# alb32r003x register map
Vendor: ALB; Series: ALB RT SoC
CPU: ALB XF, little endian
Registers are 32-bit, access not given, reset 0x0 unless marked. A register's access mark holds for its fields unless they carry their own. Offsets are from the block's base; [hi:lo] are bit positions.

## PWR — PWR: power
Base 0x29000000
0x00 PWR_CR — PWR_CR: power control register
0x04 PWR_CSR — PWR_CSR: power status register
0x08 PWR_TEST — PWR_TEST: power test register

## WDT1 — WDT1: Independent Watchdog Timer 1 for fail-safe system reset on timeout
Base 0x29002000
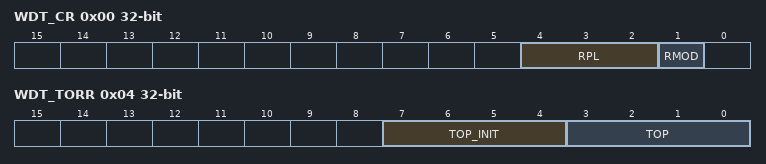
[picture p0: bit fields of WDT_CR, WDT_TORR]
0x00 WDT_CR rw — Control Register
  [4:2] RPL — Reset pulse length
    0=PCLK_CYCLES_2 (2 cycles); 1=PCLK_CYCLES_4 (4 cycles); 2=PCLK_CYCLES_8 (8 cycles); 3=PCLK_CYCLES_16 (16 cycles); 4=PCLK_CYCLES_32 (32 cycles); 5=PCLK_CYCLES_64 (64 cycles); 6=PCLK_CYCLES_128 (128 cycles); 7=PCLK_CYCLES_256 (256 cycles)
  [1] RMOD — Writes have no effect when WDT_HC_RMOD=1 (read-only)。
    0=RESET (Generate a system reset); 1=INTERRUPT (First generate an interupt and even if it is cleared by the time a second timeout occurs then generate a system reset)
0x04 WDT_TORR rw — Timeout Range Register
  [7:4] TOP_INIT — Timeout period for initialization.
    0=USER0_OR_64K (Time out of WDT_USER_TOP_INIT_0 or 64K Clocks); 1=USER1_OR_128K (Time out of WDT_USER_TOP_INIT_1 or 128K Clocks); 2=USER2_OR_256K (Time out of WDT_USER_TOP_INIT_2 or 256K Clocks); 3=USER3_OR_512K (Time out of WDT_USER_TOP_INIT_3 or 512K Clocks); 4=USER4_OR_1M (Time out of WDT_USER_TOP_INIT_4 or 1M KClocks); 5=USER5_OR_2M (Time out of WDT_USER_TOP_INIT_5 or 2M Clocks); 6=USER6_OR_4M (Time out of WDT_USER_TOP_INIT_6 or 4M Clocks); 7=USER7_OR_8M (Time out of WDT_USER_TOP_INIT_7 or 8M Clocks); 8=USER8_OR_16M (Time out of WDT_USER_TOP_INIT8_ or 16M Clocks); 9=USER9_OR_32M (Time out of WDT_USER_TOP_INIT_9 or 32M Clocks); 10=USER10_OR_64M (Time out of WDT_USER_TOP_INIT_10 or 64M Clocks); 11=USER11_OR_128M (Time out of WDT_USER_TOP_INIT_11 or 128M Clocks); 12=USER12_OR_256M (Time out of WDT_USER_TOP_INIT_12 or 256M Clocks); 13=USER13_OR_512M (Time out of WDT_USER_TOP_INIT_13 or 512M Clocks); 14=USER14_OR_1G (Time out of WDT_USER_TOP_INIT_14 or 1G Clocks); 15=USER15_OR_2G (Time out of WDT_USER_TOP_INIT_15 or 2G Clocks)
  [3:0] TOP — Timeout period
    0=USER0_OR_64K (Time out of WDT_USER_TOP_0 or 64K Clocks); 1=USER1_OR_128K (Time out of WDT_USER_TOP_1 or 128K Clocks); 2=USER2_OR_256K (Time out of WDT_USER_TOP_2 or 256K Clocks); 3=USER3_OR_512K (Time out of WDT_USER_TOP_3 or 512K Clocks); 4=USER4_OR_1M (Time out of WDT_USER_TOP_4 or 1M Clocks); 5=USER5_OR_2M (Time out of WDT_USER_TOP_5 or 2M Clocks); 6=USER6_OR_4M (Time out of WDT_USER_TOP_6 or 4M Clocks); 7=USER7_OR_8M (Time out of WDT_USER_TOP_7 or 8M Clocks); 8=USER8_OR_16M (Time out of WDT_USER_TOP_8 or 16M Clocks); 9=USER9_OR_32M (Time out of WDT_USER_TOP_9 or 32M Clocks); 10=USER10_OR_64M (Time out of WDT_USER_TOP_10 or 64M Clocks); 11=USER11_OR_128M (Time out of WDT_USER_TOP_11 or 128M Clocks); 12=USER12_OR_256M (Time out of WDT_USER_TOP_12 or 256M Clocks); 13=USER13_OR_512M (Time out of WDT_USER_TOP_13 or 512M Clocks); 14=USER14_OR_1G (Time out of WDT_USER_TOP_14 or 1G Clocks); 15=USER15_OR_2G (Time out of WDT_USER_TOP_15 or 2G Clocks)

## WWDG1 — WWDG1: Windowed Watchdog Timer 1 for time-bounded application monitoring
Base 0x29003000
0x00 CR rw reset 0x7F — CR: Global control register for module enable, mode selection and operational sequencing
  [7] WDGA — Activation bit. This bit is set to '1' by software, but it can only be cleared to '0' by hardware after reset. When WDGA=1, the watchdog can perform a reset
    0=DISABLED (Disable the watchdog); 1=ENABLED (Enable the watchdog)
0x04 CFR rw reset 0x7F — CFR: Configuration register setting timing, threshold and functional parameters
  [8:7] WDGTB[1:0] — Timer base
    0=0--0 (CK timer clock (PCLK1 divided by 4096) divided by 1); 1=0--1 (CK timer clock (PCLK1 divided by 4096) divided by 2); 2=1--0 (CK timer clock (PCLK1 divided by 4096) divided by 4); 3=1--1 (CK timer clock (PCLK1 divided by 4096) divided by 8)
0x08 SR — SR: Status register reflecting current operational state, error flags and event indicators
